AUTOSAR XML (schema 00046)
package /ComponentTypes
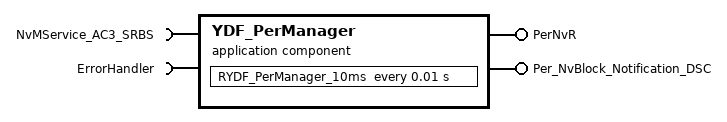
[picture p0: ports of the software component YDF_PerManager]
  application sw component type YDF_PerManager
    require port NvMService_AC3_SRBS: required-com-specs=[EraseBlock, InvalidateNvBlock, WriteBlock, ReadBlock, SetRamBlockStatus, GetErrorStatus], required-interface=NvMService_AC3_SRBS
    require port ErrorHandler: client-com-spec=ReportError, required-interface=ErrorHandler
    provide port PerNvR: provided-com-specs=[{operation=WriteRequest, queue-length=1}, {operation=ReadRequest, queue-length=1}], provided-interface=PerNvR
    provide port Per_NvBlock_Notification_DSC: nonqueued-sender-com-spec{data-element=WriteComplete, init-value=0}, provided-interface=Per_NvBlock_Notification_DSC
    behavior YDF_PerManager_InternalBehavior
      ar-typed-per-instance-memorys:
        data CriticalDataWriteCounter_PIM: type=Dt_RECORD_CriticalDataWriteCounter_PIM
      timing event TMT_RYDF_PerManager_10ms: start-on-event=RYDF_PerManager_10ms, period=0.01
      init event YDF_PerManager_InitEvent: start-on-event=RYDF_PerManager_Init
      operation invoked event OIT_PerNvR_WriteRequest_PerNvR_WriteRequest: start-on-event=PerNvR_WriteRequest, operation=PerNvR.WriteRequest
      operation invoked event OIT_PerNvR_ReadRequest_PerNvR_ReadRequest: start-on-event=PerNvR_ReadRequest, operation=PerNvR.ReadRequest
      4 x runnable:
        RYDF_PerManager_10ms
          data-send-points:
            access SEND_Per_NvBlock_Notification_DSC_WriteComplete: accessed-variable=Per_NvBlock_Notification_DSC.WriteComplete
          async call SC_ErrorHandler_ReportError: operation=ErrorHandler.ReportError
        RYDF_PerManager_Init
        PerNvR_WriteRequest
        PerNvR_ReadRequest
      swc service dependency NvMBlockNeed_CriticalDataWriteCounter_PIM: assigned-datas=role-based-data-assignment={role=ramBlock, used-data-element=CriticalDataWriteCounter_PIM}, assigned-ports=role-based-port-assignment={port-prototype=NvMService_AC3_SRBS, role=NvMService_AC3_SRBS}
        service-needs:
          nv block needs NvMBlockNeed_CriticalDataWriteCounter_PIM: check-static-block-id=false, readonly=false, reliability=ERROR-CORRECTION, resistant-to-changed-sw=true, restore-at-start=true, store-at-shutdown=false, store-cyclic=false, store-emergency=false, store-immediate=false, use-auto-validation-at-shut-down=false, use-crc-comp-mechanism=false, write-only-once=false, write-verification=false, writing-frequency=0, writing-priority=LOW
  swc implementation YDF_PerManager_Implementation: behavior=YDF_PerManager_InternalBehavior
    code-descriptors:
      code Default: artifact-descriptors=autosar-engineering-object=category=SWSRC
